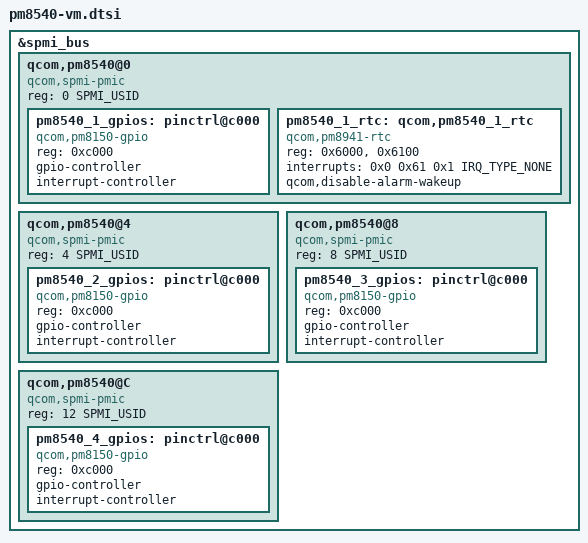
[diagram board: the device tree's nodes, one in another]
#include <dt-bindings/spmi/spmi.h>

&spmi_bus {

	qcom,pm8540@0 {
		compatible = "qcom,spmi-pmic";
		reg = <0 SPMI_USID>;
		#address-cells = <1>;
		#size-cells = <0>;

		pm8540_1_gpios: pinctrl@c000 {
			compatible = "qcom,pm8150-gpio";
			reg = <0xc000>;
			gpio-controller;
			#gpio-cells = <2>;
			interrupt-controller;
			#interrupt-cells = <2>;
		};

		pm8540_1_rtc: qcom,pm8540_1_rtc {
			compatible = "qcom,pm8941-rtc";
			reg = <0x6000>, <0x6100>;
			reg-names = "rtc", "alarm";
			interrupts = <0x0 0x61 0x1 IRQ_TYPE_NONE>;
			qcom,disable-alarm-wakeup;
		};
	};


	qcom,pm8540@4 {
		compatible = "qcom,spmi-pmic";
		reg = <4 SPMI_USID>;
		#address-cells = <1>;
		#size-cells = <0>;

		pm8540_2_gpios: pinctrl@c000 {
			compatible = "qcom,pm8150-gpio";
			reg = <0xc000>;
			gpio-controller;
			#gpio-cells = <2>;
			interrupt-controller;
			#interrupt-cells = <2>;
		};
	};

	qcom,pm8540@8 {
		compatible = "qcom,spmi-pmic";
		reg = <8 SPMI_USID>;
		#address-cells = <1>;
		#size-cells = <0>;

		pm8540_3_gpios: pinctrl@c000 {
			compatible = "qcom,pm8150-gpio";
			reg = <0xc000>;
			gpio-controller;
			#gpio-cells = <2>;
			interrupt-controller;
			#interrupt-cells = <2>;
		};
	};

	qcom,pm8540@C {
		compatible = "qcom,spmi-pmic";
		reg = <12 SPMI_USID>;
		#address-cells = <1>;
		#size-cells = <0>;

		pm8540_4_gpios: pinctrl@c000 {
			compatible = "qcom,pm8150-gpio";
			reg = <0xc000>;
			gpio-controller;
			#gpio-cells = <2>;
			interrupt-controller;
			#interrupt-cells = <2>;
		};
	};
};
